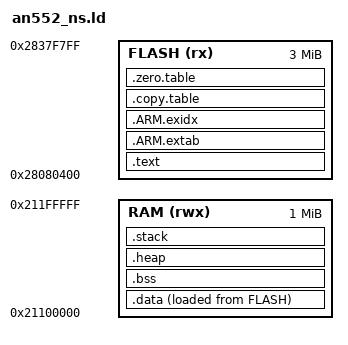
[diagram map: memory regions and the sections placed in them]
/* Copyright 2009-2023 Arm Limited and/or its affiliates
 * <open-source-office@arm.com>
 * SPDX-License-Identifier: Apache-2.0
 */

/*
 * Note: This file is based on Device/ARM/ARMCM55/Source/GCC/gcc_arm.ld from
 * the git tag 5.8.0 of the CMSIS_5 repository.
 */

__STACK_SIZE = 0x00002800;
__HEAP_SIZE  = 0x00000400;

MEMORY
{
  FLASH (rx)  : ORIGIN = (0x28080000 + 0x400), LENGTH = (0x300000 - 0x400 - 0x800)
  RAM   (rwx) : ORIGIN = 0x21100000, LENGTH = 0x00100000
}

/* Linker script to place sections and symbol values.
 * It references following symbols, which must be defined in code:
 *   Reset_Handler : Entry of reset handler
 *
 * It defines following symbols, which code can use without definition:
 *   __exidx_start
 *   __exidx_end
 *   __copy_table_start__
 *   __copy_table_end__
 *   __zero_table_start__
 *   __zero_table_end__
 *   __etext
 *   __data_start__
 *   __preinit_array_start
 *   __preinit_array_end
 *   __init_array_start
 *   __init_array_end
 *   __fini_array_start
 *   __fini_array_end
 *   __data_end__
 *   __bss_start__
 *   __bss_end__
 *   __end__
 *   end
 *   __HeapLimit
 *   __StackLimit
 *   __StackTop
 *   __stack
 */
ENTRY(Reset_Handler)

SECTIONS
{
  .text :
  {
    _vectors = .;
    KEEP(*(.vectors))
    *(.text*)

    KEEP(*(.init))
    KEEP(*(.fini))

    /* .ctors */
    *crtbegin.o(.ctors)
    *crtbegin?.o(.ctors)
    *(EXCLUDE_FILE(*crtend?.o *crtend.o) .ctors)
    *(SORT(.ctors.*))
    *(.ctors)

    /* .dtors */
    *crtbegin.o(.dtors)
    *crtbegin?.o(.dtors)
    *(EXCLUDE_FILE(*crtend?.o *crtend.o) .dtors)
    *(SORT(.dtors.*))
    *(.dtors)

    *(.rodata*)

    KEEP(*(.eh_frame*))
  } > FLASH

  .ARM.extab :
  {
    *(.ARM.extab* .gnu.linkonce.armextab.*)
  } > FLASH

  __exidx_start = .;
  .ARM.exidx :
  {
    *(.ARM.exidx* .gnu.linkonce.armexidx.*)
  } > FLASH
  __exidx_end = .;

  .copy.table :
  {
    . = ALIGN(4);
    __copy_table_start__ = .;

    LONG (LOADADDR(.data))
    LONG (ADDR(.data))
    LONG (SIZEOF(.data) / 4)

    __copy_table_end__ = .;
  } > FLASH

  .zero.table :
  {
    . = ALIGN(4);
    __zero_table_start__ = .;
    __zero_table_end__ = .;
  } > FLASH

  /**
   * Location counter can end up 2byte aligned with narrow Thumb code but
   * __etext is assumed by startup code to be the LMA of a section in RAM
   * which must be 4byte aligned.
   * This __etext variable is kept for backward compatibility with older,
   * ASM based startup files.
   */
  PROVIDE(__etext = LOADADDR(.data));

  .data : ALIGN(4)
  {
    __data_start__ = .;
    *(vtable)
    *(.data)
    *(.data.*)

    . = ALIGN(4);
    /* preinit data */
    PROVIDE_HIDDEN (__preinit_array_start = .);
    KEEP(*(.preinit_array))
    PROVIDE_HIDDEN (__preinit_array_end = .);

    . = ALIGN(4);
    /* init data */
    PROVIDE_HIDDEN (__init_array_start = .);
    KEEP(*(SORT(.init_array.*)))
    KEEP(*(.init_array))
    PROVIDE_HIDDEN (__init_array_end = .);

    . = ALIGN(4);
    /* finit data */
    PROVIDE_HIDDEN (__fini_array_start = .);
    KEEP(*(SORT(.fini_array.*)))
    KEEP(*(.fini_array))
    PROVIDE_HIDDEN (__fini_array_end = .);

    KEEP(*(.jcr*))
    . = ALIGN(4);
    /* All data end */
    __data_end__ = .;

  } > RAM AT > FLASH

  .bss :
  {
    . = ALIGN(4);
    __bss_start__ = .;
    *(.bss)
    *(.bss.*)
    *(COMMON)
    . = ALIGN(4);
    __bss_end__ = .;
  } > RAM AT > RAM

  .heap (COPY) :
  {
    . = ALIGN(8);
    __end__ = .;
    PROVIDE(end = .);
    . = . + __HEAP_SIZE;
    . = ALIGN(8);
    __HeapLimit = .;
  } > RAM
  PROVIDE(__RAM_segment_used_end__ = __HeapLimit);

  .stack (ORIGIN(RAM) + LENGTH(RAM) - __STACK_SIZE) (COPY) :
  {
    . = ALIGN(8);
    __StackLimit = .;
    . = . + __STACK_SIZE;
    . = ALIGN(8);
    __StackTop = .;
  } > RAM
  PROVIDE(__stack = __StackTop);

  /* Check if data + heap + stack exceeds RAM limit */
  ASSERT(__StackLimit >= __HeapLimit, "region RAM overflowed with stack")
}
